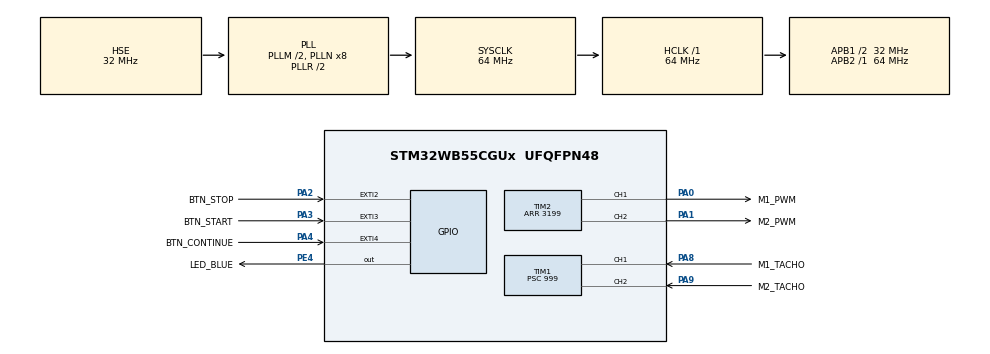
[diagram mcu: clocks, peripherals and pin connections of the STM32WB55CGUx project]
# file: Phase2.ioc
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Mcu.Family=STM32WB
Mcu.Name=STM32WB55CGUx
Mcu.Package=UFQFPN48
NVIC.EXTI2_IRQn=true\:3\:0\:true\:false\:true\:true\:true\:true
NVIC.EXTI3_IRQn=true\:3\:0\:true\:false\:true\:true\:true\:true
NVIC.EXTI4_IRQn=true\:3\:0\:true\:false\:true\:true\:true\:true
NVIC.HSEM_IRQn=true\:0\:0\:false\:false\:true\:false\:true\:true
NVIC.PriorityGroup=NVIC_PRIORITYGROUP_4
NVIC.TIM1_CC_IRQn=true\:1\:0\:true\:false\:true\:true\:true\:true
NVIC.TIM1_UP_TIM16_IRQn=true\:2\:0\:true\:false\:true\:true\:true\:true
OSC_IN.Mode=HSE-External-Oscillator
OSC_IN.Signal=RCC_OSC_IN
OSC_OUT.Mode=HSE-External-Oscillator
OSC_OUT.Signal=RCC_OSC_OUT
PA0.GPIO_Label=M1_PWM
PA0.Signal=S_TIM2_CH1
PA1.GPIO_Label=M2_PWM
PA1.Signal=S_TIM2_CH2
PA13.Mode=Serial_Wire
PA13.Signal=SYS_JTMS-SWDIO
PA14.Mode=Serial_Wire
PA14.Signal=SYS_JTCK-SWCLK
PA2.GPIO_Label=BTN_STOP
PA2.GPIO_PuPd=GPIO_PULLDOWN
PA2.Signal=GPXTI2
PA3.GPIO_Label=BTN_START
PA3.GPIO_PuPd=GPIO_PULLDOWN
PA3.Signal=GPXTI3
PA4.GPIO_Label=BTN_CONTINUE
PA4.GPIO_ModeDefaultEXTI=GPIO_MODE_IT_RISING_FALLING
PA4.GPIO_PuPd=GPIO_PULLDOWN
PA4.Signal=GPXTI4
PA8.GPIO_Label=M1_TACHO
PA8.GPIO_PuPd=GPIO_PULLUP
PA8.Signal=S_TIM1_CH1
PA9.GPIO_Label=M2_TACHO
PA9.GPIO_PuPd=GPIO_PULLUP
PA9.Signal=S_TIM1_CH2
PC14-OSC32_IN.Mode=LSE-External-Oscillator
PC14-OSC32_IN.Signal=RCC_OSC32_IN
PC15-OSC32_OUT.Mode=LSE-External-Oscillator
PC15-OSC32_OUT.Signal=RCC_OSC32_OUT
PE4.GPIO_Label=LED_BLUE
PE4.Signal=GPIO_Output
ProjectManager.HeapSize=0x200
ProjectManager.StackSize=0x400
ProjectManager.TargetToolchain=STM32CubeIDE
RCC.ADCFreq_Value=64000000
RCC.AHB2CLKDivider=RCC_SYSCLK_DIV2
RCC.AHBFreq_Value=64000000
RCC.APB1CLKDivider=RCC_HCLK_DIV2
RCC.APB1Freq_Value=32000000
RCC.APB1TimFreq_Value=64000000
RCC.APB2Freq_Value=64000000
RCC.APB2TimFreq_Value=64000000
RCC.APB3Freq_Value=16000000
RCC.CortexFreq_Value=64000000
RCC.HCLKFreq_Value=64000000
RCC.HSE_VALUE=32000000
RCC.HSI48_VALUE=48000000
RCC.HSI_VALUE=16000000
RCC.PLLM=RCC_PLLM_DIV2
RCC.PLLSourceVirtual=RCC_PLLSOURCE_HSE
RCC.SYSCLKFreq_VALUE=64000000
RCC.SYSCLKSource=RCC_SYSCLKSOURCE_PLLCLK
RCC.USBFreq_Value=64000000
RCC.VCOOutputFreq_Value=128000000
RF1.Mode=RF1_Activate
RF1.Signal=RF_RF1
SH.S_TIM1_CH1.0=TIM1_CH1,Input_Capture1_from_TI1
SH.S_TIM1_CH2.0=TIM1_CH2,Input_Capture2_from_TI2
SH.S_TIM2_CH1.0=TIM2_CH1,PWM Generation1 CH1
SH.S_TIM2_CH2.0=TIM2_CH2,PWM Generation2 CH2
STM32_WPAN.AD_SERVICE_CLASS_UUID_1=00 01
STM32_WPAN.AD_SERVICE_CLASS_UUID_1_INV=[01, 00]
STM32_WPAN.AD_SERVICE_CLASS_UUID_2=00 10
STM32_WPAN.AD_SERVICE_CLASS_UUID_2_INV=[10, 00]
STM32_WPAN.AD_SERVICE_CLASS_UUID_NBR=2
STM32_WPAN.AD_TYPE_COMPLETE_LOCAL_NAME=MotorCtrl-STM32
STM32_WPAN.AD_TYPE_COMPLETE_LOCAL_NAME_LENGTH=16
STM32_WPAN.BLE_STACK=FULL
STM32_WPAN.CFG_GAP_DEVICE_NAME=MotorCtrl
STM32_WPAN.CFG_GAP_DEVICE_NAME_LENGTH=9
STM32_WPAN.CUSTOM_P2P_SERVER=Disabled
STM32_WPAN.CUSTOM_TEMPLATE=Enabled
STM32_WPAN.INCLUDE_AD_TYPE_16_BIT_SERV_UUID_CMPLT_LIST=1
STM32_WPAN.INCLUDE_AD_TYPE_COMPLETE_LOCAL_NAME=1
STM32_WPAN.NUMBER_OF_SERVICES=2
STM32_WPAN.SERVICE1_CHAR1_LONG_NAME=TargetSpeedM1
STM32_WPAN.SERVICE1_CHAR1_PROP_READ=CHAR_PROP_READ
STM32_WPAN.SERVICE1_CHAR1_PROP_WRITE=CHAR_PROP_WRITE
STM32_WPAN.SERVICE1_CHAR1_SHORT_NAME=TSM1
STM32_WPAN.SERVICE1_CHAR1_UUID=00 02
STM32_WPAN.SERVICE1_CHAR1_UUID_TYPE=0x01
STM32_WPAN.SERVICE1_CHAR1_VALUE_LENGTH=2
STM32_WPAN.SERVICE1_CHAR2_LONG_NAME=TargetSpeedM2
STM32_WPAN.SERVICE1_CHAR2_PROP_READ=CHAR_PROP_READ
STM32_WPAN.SERVICE1_CHAR2_PROP_WRITE=CHAR_PROP_WRITE
STM32_WPAN.SERVICE1_CHAR2_SHORT_NAME=TSM2
STM32_WPAN.SERVICE1_CHAR2_UUID=00 03
STM32_WPAN.SERVICE1_CHAR2_UUID_TYPE=0x01
STM32_WPAN.SERVICE1_CHAR2_VALUE_LENGTH=2
STM32_WPAN.SERVICE1_CHAR3_LONG_NAME=CycleTime
STM32_WPAN.SERVICE1_CHAR3_PROP_READ=CHAR_PROP_READ
STM32_WPAN.SERVICE1_CHAR3_PROP_WRITE=CHAR_PROP_WRITE
STM32_WPAN.SERVICE1_CHAR3_SHORT_NAME=CT
STM32_WPAN.SERVICE1_CHAR3_UUID=00 04
STM32_WPAN.SERVICE1_CHAR3_UUID_TYPE=0x01
STM32_WPAN.SERVICE1_CHAR3_VALUE_LENGTH=2
STM32_WPAN.SERVICE1_CHAR4_LONG_NAME=Command
STM32_WPAN.SERVICE1_CHAR4_PROP_WRITE=CHAR_PROP_WRITE
STM32_WPAN.SERVICE1_CHAR4_SHORT_NAME=CMD
STM32_WPAN.SERVICE1_CHAR4_UUID=00 05
STM32_WPAN.SERVICE1_CHAR4_UUID_TYPE=0x01
STM32_WPAN.SERVICE1_LONG_NAME=Control
STM32_WPAN.SERVICE1_NUMBER_OF_CHARACTERISTICS=4
STM32_WPAN.SERVICE1_SHORT_NAME=CTRL
STM32_WPAN.SERVICE1_UUID=00 01
STM32_WPAN.SERVICE1_UUID_TYPE=0x01
STM32_WPAN.SERVICE2_CHAR1_LONG_NAME=ActualSpeedM1
STM32_WPAN.SERVICE2_CHAR1_PROP_NOTIFY=CHAR_PROP_NOTIFY
STM32_WPAN.SERVICE2_CHAR1_PROP_READ=CHAR_PROP_READ
STM32_WPAN.SERVICE2_CHAR1_SHORT_NAME=ASM1
STM32_WPAN.SERVICE2_CHAR1_UUID=00 11
STM32_WPAN.SERVICE2_CHAR1_UUID_TYPE=0x01
STM32_WPAN.SERVICE2_CHAR1_VALUE_LENGTH=2
STM32_WPAN.SERVICE2_CHAR2_LONG_NAME=ActualSpeedM2
STM32_WPAN.SERVICE2_CHAR2_PROP_NOTIFY=CHAR_PROP_NOTIFY
STM32_WPAN.SERVICE2_CHAR2_PROP_READ=CHAR_PROP_READ
STM32_WPAN.SERVICE2_CHAR2_SHORT_NAME=ASM2
STM32_WPAN.SERVICE2_CHAR2_UUID=00 12
STM32_WPAN.SERVICE2_CHAR2_UUID_TYPE=0x01
STM32_WPAN.SERVICE2_CHAR2_VALUE_LENGTH=2
STM32_WPAN.SERVICE2_CHAR3_LONG_NAME=RotationsM1
STM32_WPAN.SERVICE2_CHAR3_PROP_NOTIFY=CHAR_PROP_NOTIFY
STM32_WPAN.SERVICE2_CHAR3_PROP_READ=CHAR_PROP_READ
STM32_WPAN.SERVICE2_CHAR3_SHORT_NAME=RM1
STM32_WPAN.SERVICE2_CHAR3_UUID=00 13
STM32_WPAN.SERVICE2_CHAR3_UUID_TYPE=0x01
STM32_WPAN.SERVICE2_CHAR3_VALUE_LENGTH=4
STM32_WPAN.SERVICE2_CHAR4_LONG_NAME=RotationsM2
STM32_WPAN.SERVICE2_CHAR4_PROP_NOTIFY=CHAR_PROP_NOTIFY
STM32_WPAN.SERVICE2_CHAR4_PROP_READ=CHAR_PROP_READ
STM32_WPAN.SERVICE2_CHAR4_SHORT_NAME=RM2
STM32_WPAN.SERVICE2_CHAR4_UUID=00 14
STM32_WPAN.SERVICE2_CHAR4_UUID_TYPE=0x01
STM32_WPAN.SERVICE2_CHAR4_VALUE_LENGTH=4
STM32_WPAN.SERVICE2_CHAR5_LONG_NAME=ElapsedTime
STM32_WPAN.SERVICE2_CHAR5_PROP_NOTIFY=CHAR_PROP_NOTIFY
STM32_WPAN.SERVICE2_CHAR5_PROP_READ=CHAR_PROP_READ
STM32_WPAN.SERVICE2_CHAR5_SHORT_NAME=ET
STM32_WPAN.SERVICE2_CHAR5_UUID=00 15
STM32_WPAN.SERVICE2_CHAR5_UUID_TYPE=0x01
STM32_WPAN.SERVICE2_CHAR5_VALUE_LENGTH=2
STM32_WPAN.SERVICE2_LONG_NAME=Telemetry
STM32_WPAN.SERVICE2_NUMBER_OF_CHARACTERISTICS=5
STM32_WPAN.SERVICE2_SHORT_NAME=TELE
STM32_WPAN.SERVICE2_UUID=00 10
STM32_WPAN.SERVICE2_UUID_TYPE=0x01
TIM1.Channel-Input_Capture1_from_TI1=TIM_CHANNEL_1
TIM1.Channel-Input_Capture2_from_TI2=TIM_CHANNEL_2
TIM1.Prescaler=999
TIM16.AutoReloadPreload=TIM_AUTORELOAD_PRELOAD_ENABLE
TIM16.Period=999
TIM16.Prescaler=6399
TIM2.AutoReloadPreload=TIM_AUTORELOAD_PRELOAD_ENABLE
TIM2.Channel-PWM\ Generation1\ CH1=TIM_CHANNEL_1
TIM2.Channel-PWM\ Generation2\ CH2=TIM_CHANNEL_2
TIM2.OCPolarity_1=TIM_OCPOLARITY_LOW
TIM2.OCPolarity_2=TIM_OCPOLARITY_LOW
TIM2.Period=3199
VP_HSEM_VS_HSEM.Mode=HSEM_Activate
VP_IPCC_VS_IPCC.Mode=IPCC_Activate
VP_MEMORYMAP_VS_MEMORYMAP.Mode=CurAppReg
VP_RTC_VS_RTC_Activate.Mode=RTC_Enabled
VP_SEQUENCER_VS_SEQUENCER.Mode=SEQUENCER_Enabled
VP_STM32_WPAN_VS_BLE_HOST.Mode=STM32_WPAN_Enabled
VP_TIM16_VS_ClockSourceINT.Mode=Enable_Timer
VP_TIM1_VS_ClockSourceINT.Mode=Internal
VP_TIM2_VS_ClockSourceINT.Mode=Internal
VP_TINY_LPM_VS_TINY_LPM.Mode=TINY_LPM_Enabled
board=custom

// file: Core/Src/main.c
/* USER CODE BEGIN Header */
/**
  ******************************************************************************
  * @file           : main.c
  * @brief          : Main program body
  ******************************************************************************
  * @attention
  *
  * Copyright (c) 2026 STMicroelectronics.
  * All rights reserved.
  *
  * This software is licensed under terms that can be found in the LICENSE file
  * in the root directory of this software component.
  * If no LICENSE file comes with this software, it is provided AS-IS.
  *
  ******************************************************************************
  */
/* USER CODE END Header */
#include "main.h"

IPCC_HandleTypeDef hipcc;

RTC_HandleTypeDef hrtc;

TIM_HandleTypeDef htim1;
TIM_HandleTypeDef htim2;
TIM_HandleTypeDef htim16;

/* USER CODE BEGIN PV */
/* Application-level timer handles:
 *   htim1  — tachometer input capture  (M1 = CH1 / PA8, M2 = CH2 / PA9)
 *   htim2  — 20 kHz PWM output          (M1 = CH1 / PA0, M2 = CH2 / PA1)
 *   htim16 — 100 ms PID control tick
 */
/* USER CODE END PV */

void SystemClock_Config(void);
void PeriphCommonClock_Config(void);
static void MX_GPIO_Init(void);
static void MX_IPCC_Init(void);
static void MX_RTC_Init(void);
static void MX_TIM1_Init(void);
static void MX_TIM2_Init(void);
static void MX_TIM16_Init(void);
static void MX_RF_Init(void);

int main(void)
{

  /* MCU Configuration--------------------------------------------------------*/

  /* Reset of all peripherals, Initializes the Flash interface and the Systick. */
  HAL_Init();
  /* Config code for STM32_WPAN (HSE Tuning must be done before system clock configuration) */
  MX_APPE_Config();

  /* Configure the system clock */
  SystemClock_Config();

  /* Configure the peripherals common clocks */
  PeriphCommonClock_Config();

  /* IPCC initialisation */
  MX_IPCC_Init();

  /* Initialize all configured peripherals */
  MX_GPIO_Init();
  MX_RTC_Init();
  MX_TIM1_Init();
  MX_TIM2_Init();
  MX_TIM16_Init();
  MX_RF_Init();

  /* Init code for STM32_WPAN */
  MX_APPE_Init();

  /* Infinite loop */
  while (1)
  {
    MX_APPE_Process();

  }
}

void SystemClock_Config(void)
{
  RCC_OscInitTypeDef RCC_OscInitStruct = {0};
  RCC_ClkInitTypeDef RCC_ClkInitStruct = {0};

  /** Configure the main internal regulator output voltage
  */
  __HAL_PWR_VOLTAGESCALING_CONFIG(PWR_REGULATOR_VOLTAGE_SCALE1);

  /** Initializes the RCC Oscillators according to the specified parameters
  * in the RCC_OscInitTypeDef structure.
  */
  RCC_OscInitStruct.OscillatorType = RCC_OSCILLATORTYPE_HSI|RCC_OSCILLATORTYPE_LSI1
                              |RCC_OSCILLATORTYPE_HSE;
  RCC_OscInitStruct.HSEState = RCC_HSE_ON;
  RCC_OscInitStruct.HSIState = RCC_HSI_ON;
  RCC_OscInitStruct.HSICalibrationValue = RCC_HSICALIBRATION_DEFAULT;
  RCC_OscInitStruct.LSIState = RCC_LSI_ON;
  RCC_OscInitStruct.PLL.PLLState = RCC_PLL_ON;
  RCC_OscInitStruct.PLL.PLLSource = RCC_PLLSOURCE_HSE;
  RCC_OscInitStruct.PLL.PLLM = RCC_PLLM_DIV2;
  RCC_OscInitStruct.PLL.PLLN = 8;
  RCC_OscInitStruct.PLL.PLLP = RCC_PLLP_DIV2;
  RCC_OscInitStruct.PLL.PLLR = RCC_PLLR_DIV2;
  RCC_OscInitStruct.PLL.PLLQ = RCC_PLLQ_DIV2;
  if (HAL_RCC_OscConfig(&RCC_OscInitStruct) != HAL_OK)
  {
    Error_Handler();
  }

  /** Configure the SYSCLKSource, HCLK, PCLK1 and PCLK2 clocks dividers
  */
  RCC_ClkInitStruct.ClockType = RCC_CLOCKTYPE_HCLK4|RCC_CLOCKTYPE_HCLK2
                              |RCC_CLOCKTYPE_HCLK|RCC_CLOCKTYPE_SYSCLK
                              |RCC_CLOCKTYPE_PCLK1|RCC_CLOCKTYPE_PCLK2;
  RCC_ClkInitStruct.SYSCLKSource = RCC_SYSCLKSOURCE_PLLCLK;
  RCC_ClkInitStruct.AHBCLKDivider = RCC_SYSCLK_DIV1;
  RCC_ClkInitStruct.APB1CLKDivider = RCC_HCLK_DIV2;
  RCC_ClkInitStruct.APB2CLKDivider = RCC_HCLK_DIV1;
  RCC_ClkInitStruct.AHBCLK2Divider = RCC_SYSCLK_DIV2;
  RCC_ClkInitStruct.AHBCLK4Divider = RCC_SYSCLK_DIV1;

  if (HAL_RCC_ClockConfig(&RCC_ClkInitStruct, FLASH_LATENCY_3) != HAL_OK)
  {
    Error_Handler();
  }
}

void PeriphCommonClock_Config(void)
{
  RCC_PeriphCLKInitTypeDef PeriphClkInitStruct = {0};

  /** Initializes the peripherals clock
  */
  PeriphClkInitStruct.PeriphClockSelection = RCC_PERIPHCLK_SMPS|RCC_PERIPHCLK_RFWAKEUP;
  PeriphClkInitStruct.RFWakeUpClockSelection = RCC_RFWKPCLKSOURCE_HSE_DIV1024;
  PeriphClkInitStruct.SmpsClockSelection = RCC_SMPSCLKSOURCE_HSI;
  PeriphClkInitStruct.SmpsDivSelection = RCC_SMPSCLKDIV_RANGE1;

  if (HAL_RCCEx_PeriphCLKConfig(&PeriphClkInitStruct) != HAL_OK)
  {
    Error_Handler();
  }
}

static void MX_IPCC_Init(void)
{

  hipcc.Instance = IPCC;
  if (HAL_IPCC_Init(&hipcc) != HAL_OK)
  {
    Error_Handler();
  }

}

static void MX_RF_Init(void)
{

}

static void MX_RTC_Init(void)
{

  /** Initialize RTC Only
  */
  hrtc.Instance = RTC;
  hrtc.Init.HourFormat = RTC_HOURFORMAT_24;
  hrtc.Init.AsynchPrediv = CFG_RTC_ASYNCH_PRESCALER;
  hrtc.Init.SynchPrediv = CFG_RTC_SYNCH_PRESCALER;
  hrtc.Init.OutPut = RTC_OUTPUT_DISABLE;
  hrtc.Init.OutPutPolarity = RTC_OUTPUT_POLARITY_HIGH;
  hrtc.Init.OutPutType = RTC_OUTPUT_TYPE_OPENDRAIN;
  hrtc.Init.OutPutRemap = RTC_OUTPUT_REMAP_NONE;
  if (HAL_RTC_Init(&hrtc) != HAL_OK)
  {
    Error_Handler();
  }

}

static void MX_TIM1_Init(void)
{

  /* USER CODE BEGIN TIM1_Init 0 */
  /* Tachometer input capture for both BLDC motors.
   * Motor 1 tachometer → CH1 (PA8)
   * Motor 2 tachometer → CH2 (PA9)
   * Prescaler 999 → timer counts at 64 kHz.  ICFilter = 15 suppresses noise.
   * IC interrupt started/stopped by Motor_Start() / Motor_Stop() in custom_app.c.
   */
  /* USER CODE END TIM1_Init 0 */

  TIM_ClockConfigTypeDef sClockSourceConfig = {0};
  TIM_MasterConfigTypeDef sMasterConfig = {0};
  TIM_IC_InitTypeDef sConfigIC = {0};

  htim1.Instance = TIM1;
  htim1.Init.Prescaler = 999;
  htim1.Init.CounterMode = TIM_COUNTERMODE_UP;
  htim1.Init.Period = 65535;
  htim1.Init.ClockDivision = TIM_CLOCKDIVISION_DIV1;
  htim1.Init.RepetitionCounter = 0;
  htim1.Init.AutoReloadPreload = TIM_AUTORELOAD_PRELOAD_DISABLE;
  if (HAL_TIM_Base_Init(&htim1) != HAL_OK)
  {
    Error_Handler();
  }
  sClockSourceConfig.ClockSource = TIM_CLOCKSOURCE_INTERNAL;
  if (HAL_TIM_ConfigClockSource(&htim1, &sClockSourceConfig) != HAL_OK)
  {
    Error_Handler();
  }
  if (HAL_TIM_IC_Init(&htim1) != HAL_OK)
  {
    Error_Handler();
  }
  sMasterConfig.MasterOutputTrigger = TIM_TRGO_RESET;
  sMasterConfig.MasterOutputTrigger2 = TIM_TRGO2_RESET;
  sMasterConfig.MasterSlaveMode = TIM_MASTERSLAVEMODE_DISABLE;
  if (HAL_TIMEx_MasterConfigSynchronization(&htim1, &sMasterConfig) != HAL_OK)
  {
    Error_Handler();
  }
  sConfigIC.ICPolarity = TIM_INPUTCHANNELPOLARITY_RISING;
  sConfigIC.ICSelection = TIM_ICSELECTION_DIRECTTI;
  sConfigIC.ICPrescaler = TIM_ICPSC_DIV1;
  sConfigIC.ICFilter = 0;
  if (HAL_TIM_IC_ConfigChannel(&htim1, &sConfigIC, TIM_CHANNEL_1) != HAL_OK)
  {
    Error_Handler();
  }
  if (HAL_TIM_IC_ConfigChannel(&htim1, &sConfigIC, TIM_CHANNEL_2) != HAL_OK)
  {
    Error_Handler();
  }

}

static void MX_TIM2_Init(void)
{

  /* USER CODE BEGIN TIM2_Init 0 */
  /* 20 kHz PWM output for both BLDC motors.
   * Motor 1 PWM → CH1 (PA0),  Motor 2 PWM → CH2 (PA1)
   * Prescaler 0, Period 3199 → 64 MHz / 3200 = 20 kHz.
   * Active-LOW polarity (OCPolarity_LOW) to match the motor driver hardware.
   * Duty cycle controlled by Motor_SetDuty() via __HAL_TIM_SET_COMPARE().
   */
  /* USER CODE END TIM2_Init 0 */

  TIM_ClockConfigTypeDef sClockSourceConfig = {0};
  TIM_MasterConfigTypeDef sMasterConfig = {0};
  TIM_OC_InitTypeDef sConfigOC = {0};

  htim2.Instance = TIM2;
  htim2.Init.Prescaler = 0;
  htim2.Init.CounterMode = TIM_COUNTERMODE_UP;
  htim2.Init.Period = 3199;
  htim2.Init.ClockDivision = TIM_CLOCKDIVISION_DIV1;
  htim2.Init.AutoReloadPreload = TIM_AUTORELOAD_PRELOAD_ENABLE;
  if (HAL_TIM_Base_Init(&htim2) != HAL_OK)
  {
    Error_Handler();
  }
  sClockSourceConfig.ClockSource = TIM_CLOCKSOURCE_INTERNAL;
  if (HAL_TIM_ConfigClockSource(&htim2, &sClockSourceConfig) != HAL_OK)
  {
    Error_Handler();
  }
  if (HAL_TIM_PWM_Init(&htim2) != HAL_OK)
  {
    Error_Handler();
  }
  sMasterConfig.MasterOutputTrigger = TIM_TRGO_RESET;
  sMasterConfig.MasterSlaveMode = TIM_MASTERSLAVEMODE_DISABLE;
  if (HAL_TIMEx_MasterConfigSynchronization(&htim2, &sMasterConfig) != HAL_OK)
  {
    Error_Handler();
  }
  sConfigOC.OCMode = TIM_OCMODE_PWM1;
  sConfigOC.Pulse = 0;
  sConfigOC.OCPolarity = TIM_OCPOLARITY_LOW;
  sConfigOC.OCFastMode = TIM_OCFAST_DISABLE;
  if (HAL_TIM_PWM_ConfigChannel(&htim2, &sConfigOC, TIM_CHANNEL_1) != HAL_OK)
  {
    Error_Handler();
  }
  if (HAL_TIM_PWM_ConfigChannel(&htim2, &sConfigOC, TIM_CHANNEL_2) != HAL_OK)
  {
    Error_Handler();
  }
  /* USER CODE BEGIN TIM2_Init 2 */
  /* PWM polarity driven by MOTOR_MODE (see main.h). Re-applied here so it
   * survives CubeMX regeneration of the OCPolarity line above. */
  sConfigOC.OCPolarity = MOTOR_PWM_POL;
  HAL_TIM_PWM_ConfigChannel(&htim2, &sConfigOC, TIM_CHANNEL_1);
  HAL_TIM_PWM_ConfigChannel(&htim2, &sConfigOC, TIM_CHANNEL_2);
  /* USER CODE END TIM2_Init 2 */
  HAL_TIM_MspPostInit(&htim2);

}

static void MX_TIM16_Init(void)
{

  /* USER CODE BEGIN TIM16_Init 0 */
  /* 100 ms PID control tick for both motors.
   * Prescaler 6399, Period 999 → 64 MHz / 6400 / 1000 = 10 Hz = 100 ms per tick.
   * Fires HAL_TIM_PeriodElapsedCallback() which runs Motor_UpdatePID(),
   * increments the cycle timer, and triggers the BLE telemetry task.
   * Timer is started by Motor_StartAll() and stopped by Motor_StopAll().
   */
  /* USER CODE END TIM16_Init 0 */

  htim16.Instance = TIM16;
  htim16.Init.Prescaler = 6399;
  htim16.Init.CounterMode = TIM_COUNTERMODE_UP;
  htim16.Init.Period = 999;
  htim16.Init.ClockDivision = TIM_CLOCKDIVISION_DIV1;
  htim16.Init.RepetitionCounter = 0;
  htim16.Init.AutoReloadPreload = TIM_AUTORELOAD_PRELOAD_ENABLE;
  if (HAL_TIM_Base_Init(&htim16) != HAL_OK)
  {
    Error_Handler();
  }

}

static void MX_GPIO_Init(void)
{
  GPIO_InitTypeDef GPIO_InitStruct = {0};
  /* USER CODE BEGIN MX_GPIO_Init_1 */
  /* Motor control buttons (GPIOA, active-HIGH, pull-down):
   *   PA2 BTN_STOP     — rising-edge EXTI; stop motors immediately (any mode)
   *   PA3 BTN_START    — rising-edge EXTI; start timed run (35 s by default)
   *   PA4 BTN_CONTINUE — both-edge EXTI; run while held, release stops motors
   * Debounce: first-edge-wins timestamp filter in HAL_GPIO_EXTI_Callback().
   *
   * Status LED:
   *   PE4 LED_BLUE — ON while motors running, blinks 5 Hz (PID tick heartbeat)
   */
  /* USER CODE END MX_GPIO_Init_1 */

  /* GPIO Ports Clock Enable */
  __HAL_RCC_GPIOC_CLK_ENABLE();
  __HAL_RCC_GPIOA_CLK_ENABLE();
  __HAL_RCC_GPIOE_CLK_ENABLE();

  /*Configure GPIO pin Output Level */
  HAL_GPIO_WritePin(LED_BLUE_GPIO_Port, LED_BLUE_Pin, GPIO_PIN_RESET);

  /*Configure GPIO pins : BTN_STOP_Pin BTN_START_Pin */
  GPIO_InitStruct.Pin = BTN_STOP_Pin|BTN_START_Pin;
  GPIO_InitStruct.Mode = GPIO_MODE_IT_RISING;
  GPIO_InitStruct.Pull = GPIO_PULLDOWN;
  HAL_GPIO_Init(GPIOA, &GPIO_InitStruct);

  /*Configure GPIO pin : BTN_CONTINUE_Pin */
  GPIO_InitStruct.Pin = BTN_CONTINUE_Pin;
  GPIO_InitStruct.Mode = GPIO_MODE_IT_RISING_FALLING;
  GPIO_InitStruct.Pull = GPIO_PULLDOWN;
  HAL_GPIO_Init(BTN_CONTINUE_GPIO_Port, &GPIO_InitStruct);

  /*Configure GPIO pin : LED_BLUE_Pin */
  GPIO_InitStruct.Pin = LED_BLUE_Pin;
  GPIO_InitStruct.Mode = GPIO_MODE_OUTPUT_PP;
  GPIO_InitStruct.Pull = GPIO_NOPULL;
  GPIO_InitStruct.Speed = GPIO_SPEED_FREQ_LOW;
  HAL_GPIO_Init(LED_BLUE_GPIO_Port, &GPIO_InitStruct);

  /* EXTI interrupt init*/
  HAL_NVIC_SetPriority(EXTI2_IRQn, 3, 0);
  HAL_NVIC_EnableIRQ(EXTI2_IRQn);

  HAL_NVIC_SetPriority(EXTI3_IRQn, 3, 0);
  HAL_NVIC_EnableIRQ(EXTI3_IRQn);

  HAL_NVIC_SetPriority(EXTI4_IRQn, 3, 0);
  HAL_NVIC_EnableIRQ(EXTI4_IRQn);

}

void Error_Handler(void)
{
  __disable_irq();
  while (1)
  {
  }
}
